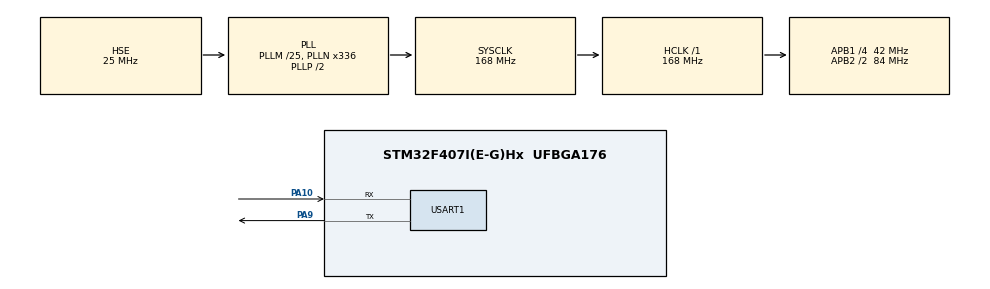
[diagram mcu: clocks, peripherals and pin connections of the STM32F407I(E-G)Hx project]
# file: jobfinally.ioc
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FREERTOS.Queues01=xEnvDataQueue,10,20,1,Dynamic,NULL,NULL;xControlCmdQueue,10,8,1,Dynamic,NULL,NULL;xLogQueue,20,16,1,Dynamic,NULL,NULL;xUartRxQueue,64,1,1,Dynamic,NULL,NULL
FREERTOS.Tasks01=defaultTask,0,128,StartDefaultTask,Default,NULL,Dynamic,NULL,NULL;Task_Sensor,1,512,StartTask02,Default,NULL,Dynamic,NULL,NULL;Task_Control,2,512,StartTask03,Default,NULL,Dynamic,NULL,NULL;Task_TouchUI,0,1024,StartTask04,Default,NULL,Dynamic,NULL,NULL;Task_Com,0,512,StartTask05,Default,NULL,Dynamic,NULL,NULL;Task_Logger,-2,512,StartTask06,Default,NULL,Dynamic,NULL,NULL
FREERTOS.configUSE_COUNTING_SEMAPHORES=1
Mcu.Family=STM32F4
Mcu.Name=STM32F407I(E-G)Hx
Mcu.Package=UFBGA176
NVIC.PriorityGroup=NVIC_PRIORITYGROUP_4
NVIC.TIM1_UP_TIM10_IRQn=true\:15\:0\:false\:false\:true\:false\:false\:true\:true
NVIC.TimeBase=TIM1_UP_TIM10_IRQn
NVIC.TimeBaseIP=TIM1
NVIC.USART1_IRQn=true\:5\:0\:false\:false\:true\:true\:true\:true\:true
PA10.Mode=Asynchronous
PA10.Signal=USART1_RX
PA13.Mode=Serial_Wire
PA13.Signal=SYS_JTMS-SWDIO
PA14.Mode=Serial_Wire
PA14.Signal=SYS_JTCK-SWCLK
PA9.Mode=Asynchronous
PA9.Signal=USART1_TX
PH0-OSC_IN.Mode=HSE-External-Oscillator
PH0-OSC_IN.Signal=RCC_OSC_IN
PH1-OSC_OUT.Mode=HSE-External-Oscillator
PH1-OSC_OUT.Signal=RCC_OSC_OUT
ProjectManager.HeapSize=0x200
ProjectManager.StackSize=0x400
ProjectManager.TargetToolchain=MDK-ARM V5.27
RCC.48MHZClocksFreq_Value=84000000
RCC.AHBFreq_Value=168000000
RCC.APB1CLKDivider=RCC_HCLK_DIV4
RCC.APB1Freq_Value=42000000
RCC.APB1TimFreq_Value=84000000
RCC.APB2CLKDivider=RCC_HCLK_DIV2
RCC.APB2Freq_Value=84000000
RCC.APB2TimFreq_Value=168000000
RCC.CortexFreq_Value=168000000
RCC.HCLKFreq_Value=168000000
RCC.HSE_VALUE=25000000
RCC.HSI_VALUE=16000000
RCC.LSE_VALUE=32768
RCC.PLLM=25
RCC.PLLN=336
RCC.PLLSourceVirtual=RCC_PLLSOURCE_HSE
RCC.SYSCLKFreq_VALUE=168000000
RCC.SYSCLKSource=RCC_SYSCLKSOURCE_PLLCLK
RCC.VCOOutputFreq_Value=336000000
USART1.VirtualMode=VM_ASYNC
VP_FREERTOS_VS_CMSIS_V1.Mode=CMSIS_V1
VP_SYS_VS_tim1.Mode=TIM1
board=custom

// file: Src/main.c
/* USER CODE BEGIN Header */
/**
  ******************************************************************************
  * @file           : main.c
  * @brief          : Main program body
  ******************************************************************************
  * @attention
  *
  * Copyright (c) 2025 STMicroelectronics.
  * All rights reserved.
  *
  * This software is licensed under terms that can be found in the LICENSE file
  * in the root directory of this software component.
  * If no LICENSE file comes with this software, it is provided AS-IS.
  *
  ******************************************************************************
  */
/* USER CODE END Header */
#include "main.h"
#include "cmsis_os.h"
#include "usart.h"
#include "gpio.h"

void SystemClock_Config(void);
void MX_FREERTOS_Init(void);

int main(void)
{

  /* MCU Configuration--------------------------------------------------------*/

  /* Reset of all peripherals, Initializes the Flash interface and the Systick. */
  HAL_Init();

  /* Configure the system clock */
  SystemClock_Config();

  /* Initialize all configured peripherals */
  MX_GPIO_Init();
  MX_USART1_UART_Init();
  /* USER CODE BEGIN 2 */
  __HAL_UART_ENABLE_IT(&huart1, UART_IT_RXNE);
  /* USER CODE END 2 */

  /* Call init function for freertos objects (in cmsis_os2.c) */
  MX_FREERTOS_Init();

  /* Start scheduler */
  osKernelStart();

  /* We should never get here as control is now taken by the scheduler */

  /* Infinite loop */
  while (1)
  {

  }
}

void SystemClock_Config(void)
{
  RCC_OscInitTypeDef RCC_OscInitStruct = {0};
  RCC_ClkInitTypeDef RCC_ClkInitStruct = {0};

  /** Configure the main internal regulator output voltage
  */
  __HAL_RCC_PWR_CLK_ENABLE();
  __HAL_PWR_VOLTAGESCALING_CONFIG(PWR_REGULATOR_VOLTAGE_SCALE1);

  /** Initializes the RCC Oscillators according to the specified parameters
  * in the RCC_OscInitTypeDef structure.
  */
  RCC_OscInitStruct.OscillatorType = RCC_OSCILLATORTYPE_HSE;
  RCC_OscInitStruct.HSEState = RCC_HSE_ON;
  RCC_OscInitStruct.PLL.PLLState = RCC_PLL_ON;
  RCC_OscInitStruct.PLL.PLLSource = RCC_PLLSOURCE_HSE;
  RCC_OscInitStruct.PLL.PLLM = 25;
  RCC_OscInitStruct.PLL.PLLN = 336;
  RCC_OscInitStruct.PLL.PLLP = RCC_PLLP_DIV2;
  RCC_OscInitStruct.PLL.PLLQ = 4;
  if (HAL_RCC_OscConfig(&RCC_OscInitStruct) != HAL_OK)
  {
    Error_Handler();
  }

  /** Initializes the CPU, AHB and APB buses clocks
  */
  RCC_ClkInitStruct.ClockType = RCC_CLOCKTYPE_HCLK|RCC_CLOCKTYPE_SYSCLK
                              |RCC_CLOCKTYPE_PCLK1|RCC_CLOCKTYPE_PCLK2;
  RCC_ClkInitStruct.SYSCLKSource = RCC_SYSCLKSOURCE_PLLCLK;
  RCC_ClkInitStruct.AHBCLKDivider = RCC_SYSCLK_DIV1;
  RCC_ClkInitStruct.APB1CLKDivider = RCC_HCLK_DIV4;
  RCC_ClkInitStruct.APB2CLKDivider = RCC_HCLK_DIV2;

  if (HAL_RCC_ClockConfig(&RCC_ClkInitStruct, FLASH_LATENCY_5) != HAL_OK)
  {
    Error_Handler();
  }
}

void HAL_TIM_PeriodElapsedCallback(TIM_HandleTypeDef *htim)
{
  if (htim->Instance == TIM1) {
    HAL_IncTick();
  }
}

void Error_Handler(void)
{
  __disable_irq();
  while (1)
  {
  }
}

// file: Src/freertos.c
/* USER CODE BEGIN Header */
/**
  ******************************************************************************
  * File Name          : freertos.c
  * Description        : Code for freertos applications
  ******************************************************************************
  * @attention
  *
  * Copyright (c) 2025 STMicroelectronics.
  * All rights reserved.
  *
  * This software is licensed under terms that can be found in the LICENSE file
  * in the root directory of this software component.
  * If no LICENSE file comes with this software, it is provided AS-IS.
  *
  ******************************************************************************
  */
/* USER CODE END Header */

#include "FreeRTOS.h"
#include "task.h"
#include "main.h"
#include "cmsis_os.h"

/* USER CODE BEGIN Includes */
#include "communication.h"
#include <string.h>
/* USER CODE END Includes */

/* USER CODE BEGIN Variables */
typedef struct {
    uint8_t fan_speed;
    uint8_t light_status;
    uint8_t alarm_status;
    uint8_t system_mode;
} control_status_t;

control_status_t control_status = {50, 1, 0, 0};
/* USER CODE END Variables */
osThreadId defaultTaskHandle;
osThreadId Task_SensorHandle;
osThreadId Task_ControlHandle;
osThreadId Task_TouchUIHandle;
osThreadId Task_ComHandle;
osThreadId Task_LoggerHandle;
osMessageQId xEnvDataQueueHandle;
osMessageQId xControlCmdQueueHandle;
osMessageQId xLogQueueHandle;
osMessageQId xUartRxQueueHandle;

void StartDefaultTask(void const * argument);
void StartTask02(void const * argument);
void StartTask03(void const * argument);
void StartTask04(void const * argument);
void StartTask05(void const * argument);
void StartTask06(void const * argument);

void MX_FREERTOS_Init(void); /* (MISRA C 2004 rule 8.1) */

/* GetIdleTaskMemory prototype (linked to static allocation support) */
void vApplicationGetIdleTaskMemory( StaticTask_t **ppxIdleTaskTCBBuffer, StackType_t **ppxIdleTaskStackBuffer, uint32_t *pulIdleTaskStackSize );

/* USER CODE BEGIN GET_IDLE_TASK_MEMORY */
static StaticTask_t xIdleTaskTCBBuffer;
static StackType_t xIdleStack[configMINIMAL_STACK_SIZE];

void vApplicationGetIdleTaskMemory( StaticTask_t **ppxIdleTaskTCBBuffer, StackType_t **ppxIdleTaskStackBuffer, uint32_t *pulIdleTaskStackSize )
{
  *ppxIdleTaskTCBBuffer = &xIdleTaskTCBBuffer;
  *ppxIdleTaskStackBuffer = &xIdleStack[0];
  *pulIdleTaskStackSize = configMINIMAL_STACK_SIZE;
  /* place for user code */
}
/* USER CODE END GET_IDLE_TASK_MEMORY */

void MX_FREERTOS_Init(void) {

  /* Create the queue(s) */
  /* definition and creation of xEnvDataQueue */
  osMessageQDef(xEnvDataQueue, 10, 20);
  xEnvDataQueueHandle = osMessageCreate(osMessageQ(xEnvDataQueue), NULL);

  /* definition and creation of xControlCmdQueue */
  osMessageQDef(xControlCmdQueue, 10, 8);
  xControlCmdQueueHandle = osMessageCreate(osMessageQ(xControlCmdQueue), NULL);

  /* definition and creation of xLogQueue */
  osMessageQDef(xLogQueue, 20, 16);
  xLogQueueHandle = osMessageCreate(osMessageQ(xLogQueue), NULL);

  /* definition and creation of xUartRxQueue */
  osMessageQDef(xUartRxQueue, 64, 1);
  xUartRxQueueHandle = osMessageCreate(osMessageQ(xUartRxQueue), NULL);

  /* Create the thread(s) */
  /* definition and creation of defaultTask */
  osThreadDef(defaultTask, StartDefaultTask, osPriorityNormal, 0, 128);
  defaultTaskHandle = osThreadCreate(osThread(defaultTask), NULL);

  /* definition and creation of Task_Sensor */
  osThreadDef(Task_Sensor, StartTask02, osPriorityAboveNormal, 0, 512);
  Task_SensorHandle = osThreadCreate(osThread(Task_Sensor), NULL);

  /* definition and creation of Task_Control */
  osThreadDef(Task_Control, StartTask03, osPriorityHigh, 0, 512);
  Task_ControlHandle = osThreadCreate(osThread(Task_Control), NULL);

  /* definition and creation of Task_TouchUI */
  osThreadDef(Task_TouchUI, StartTask04, osPriorityNormal, 0, 1024);
  Task_TouchUIHandle = osThreadCreate(osThread(Task_TouchUI), NULL);

  /* definition and creation of Task_Com */
  osThreadDef(Task_Com, StartTask05, osPriorityNormal, 0, 512);
  Task_ComHandle = osThreadCreate(osThread(Task_Com), NULL);

  /* definition and creation of Task_Logger */
  osThreadDef(Task_Logger, StartTask06, osPriorityLow, 0, 512);
  Task_LoggerHandle = osThreadCreate(osThread(Task_Logger), NULL);

}

void StartDefaultTask(void const * argument)
{
  for(;;)
  {
    osDelay(1);
  }
}

void StartTask02(void const * argument)
{
  for(;;)
  {
    osDelay(1);
  }
}

void StartTask03(void const * argument)
{
  for(;;)
  {
    osDelay(1);
  }
}

void StartTask04(void const * argument)
{
  for(;;)
  {
    osDelay(1);
  }
}

void StartTask05(void const * argument)
{
  /* USER CODE BEGIN StartTask05 */
  /* Infinite loop */
  data_frame_t data_frame;
  env_data_t env_data;
  uint32_t last_wake_time = osKernelSysTick();

  // ??????
  data_frame.header[0] = 0xAA;
  data_frame.header[1] = 0x55;
  data_frame.device_id = 0x01;
  data_frame.frame_type = 0x01;
  data_frame.tail[0] = 0x0D;
  data_frame.tail[1] = 0x0A;

  for(;;)
  {
    osDelayUntil(&last_wake_time, 500);

    osEvent event = osMessageGet(xEnvDataQueueHandle, 0);
    if (event.status == osEventMessage) {
        memcpy(&env_data, (env_data_t*)event.value.p, sizeof(env_data_t));

        data_frame.timestamp = osKernelSysTick();
        data_frame.temperature = env_data.temperature;
        data_frame.light_intensity = env_data.light_intensity;
        data_frame.smoke_value = env_data.smoke_value;
        data_frame.flame_value = env_data.flame_value;
        data_frame.door_status = env_data.door_status;
        data_frame.fan_speed = control_status.fan_speed;
        data_frame.light_status = control_status.light_status;
        data_frame.alarm_status = control_status.alarm_status;
        data_frame.system_mode = control_status.system_mode;

        data_frame.crc16 = calculate_crc16((uint8_t*)&data_frame, sizeof(data_frame_t) - 4);

        uart_send_data((uint8_t*)&data_frame, sizeof(data_frame_t));
    } else {
        data_frame.timestamp = osKernelSysTick();
        data_frame.temperature = 25.5f;
        data_frame.light_intensity = 300.0f;
        data_frame.smoke_value = 50.0f;
        data_frame.flame_value = 0.0f;
        data_frame.door_status = 0;
        data_frame.fan_speed = control_status.fan_speed;
        data_frame.light_status = control_status.light_status;
        data_frame.alarm_status = control_status.alarm_status;
        data_frame.system_mode = control_status.system_mode;
        data_frame.crc16 = calculate_crc16((uint8_t*)&data_frame, sizeof(data_frame_t) - 4);
        uart_send_data((uint8_t*)&data_frame, sizeof(data_frame_t));
    }

    process_received_commands();
  }
  /* USER CODE END StartTask05 */
}

void StartTask06(void const * argument)
{
  /* USER CODE BEGIN StartTask06 */
  /* Infinite loop */
  uint32_t log_data;
  for(;;)
  {
    log_data = osKernelSysTick();
    osMessagePut(xLogQueueHandle, log_data, 0);
    osDelay(10000);
  }
  /* USER CODE END StartTask06 */
}
